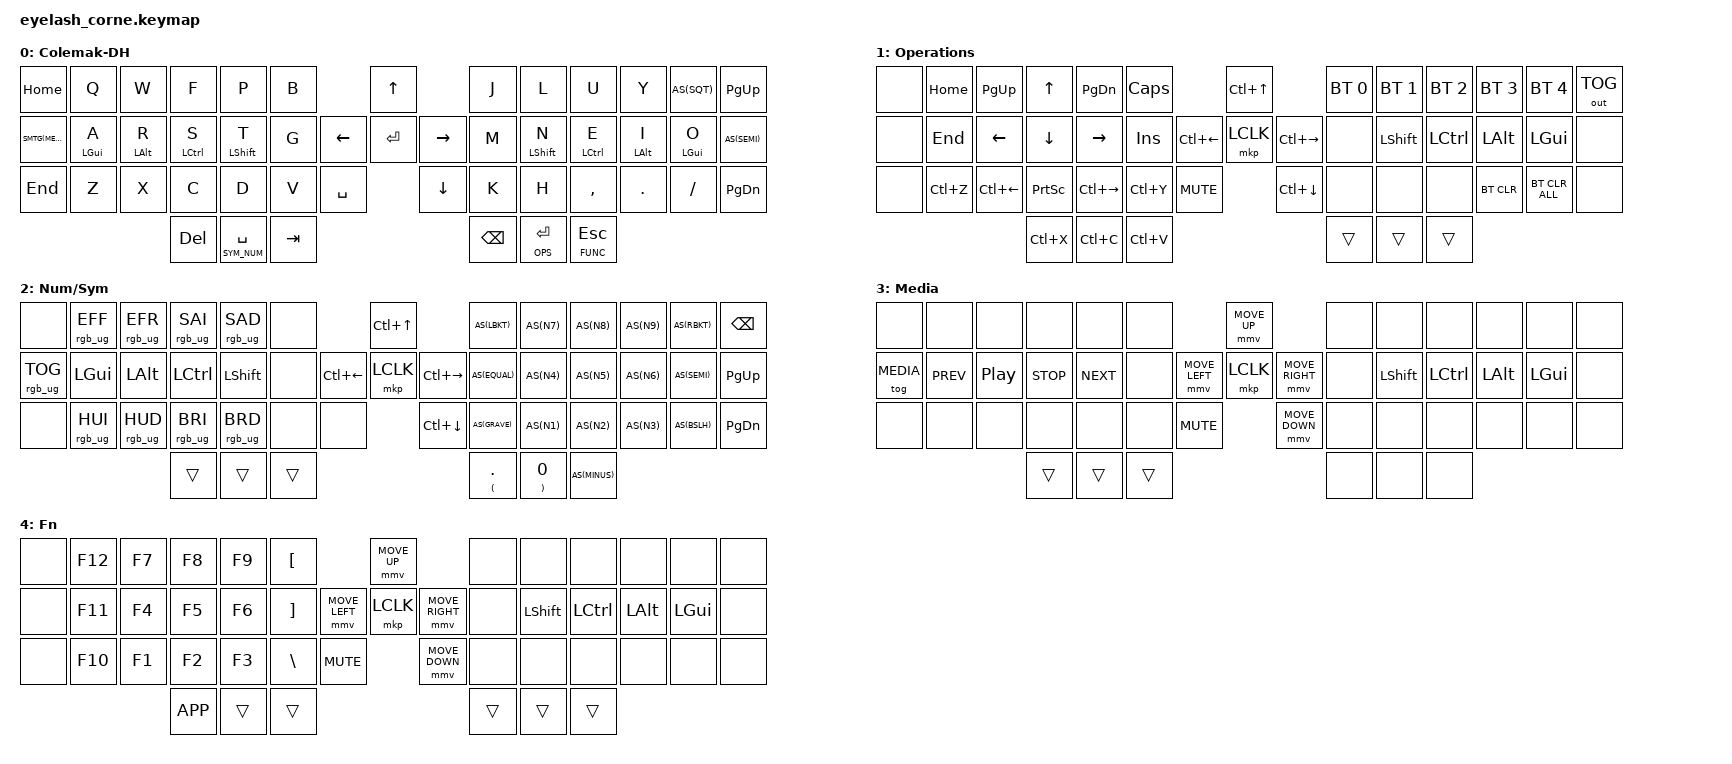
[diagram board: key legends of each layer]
#define ZMK_POINTING_DEFAULT_MOVE_VAL 1200  // 600
#define ZMK_POINTING_DEFAULT_SCRL_VAL 25   // 10

#define AS(keycode)     &as LS(keycode) keycode     // Autoshift Macro
#define SMTG(keycode)   &smtg keycode keycode

/*                42 KEY MATRIX with ENCODER and JOYSTICK / LAYOUT MAPPING

based on Aliexpress variation of Foostan corne
https://github.com/a741725193/zmk-new_corne/blob/main/README_EN.md

  ╭────────────────────────╮             ╭────╮      ╭─────────────────────────╮
  │  0   1   2   3   4   5 │         ╭───╯  6 ╰───╮  │   7   8   9  10  11  12 │
  │ 13  14  15  16  17  18 │ ╭────╮  │ 19  20  21 │  │  22  23  24  25  26  27 │
  │ 28  29  30  31  32  33 │ │ 34 │  ╰───╮ 35 ╭───╯  │  36  37  38  39  40  41 │
  ╰───────────╮ 42  43  44 │ ╰────╯      ╰────╯      │  45  46  47 ╭───────────╯
              ╰────────────╯                         ╰─────────────╯

  ╭──────────────────────────────╮              ╭─────╮      ╭──────────────────────────────╮
  │ LT5  LT4  LT3  LT2  LT1  LT0 │          ╭───╯ JS0 ╰───╮  │ RT0  RT1  RT2  RT3  RT4  RT5 │
  │ LM5  LM4  LM3  LM2  LM1  LM0 │ ╭─────╮  │ JS1 JS2 JS3 │  │ RM0  RM1  RM2  RM3  RM4  RM5 │
  │ LB5  LB4  LB3  LB2  LB1  LB0 │ │ LEC │  ╰───╮ JS4 ╭───╯  │ RB0  RB1  RB2  RB3  RB4  RB5 │
  ╰──────────────╮ LH2  LH1  LH0 │ ╰─────╯      ╰─────╯      │ RH0  RH1  RH2 ╭──────────────╯
                 ╰───────────────╯                           ╰───────────────╯

*/

#define KEYS_L LT0 LT1 LT2 LT3 LT4 LT5 LM0 LM1 LM2 LM3 LM4 LM5 LB0 LB1 LB2 LB3 LB4 LB5
#define KEYS_R RT0 RT1 RT2 RT3 RT4 RT5 RM0 RM1 RM2 RM3 RM4 RM5 RB0 RB1 RB2 RB3 RB4 RB5
#define HMOD_L LM1 LM2 LM3 LM4
#define HMOD_R RM1 RM2 RM3 RM4
#define THUMB_L LH2 LH1 LH0
#define THUMB_R RH0 RH1 RH2

#define COL_DH  0
#define OPS     1
#define SYM_NUM 2
#define MEDIA   3
#define FUNC    4

#include <input/processors.dtsi>
#include <zephyr/dt-bindings/input/input-event-codes.h>
#include <behaviors.dtsi>
#include <dt-bindings/zmk/bt.h>
#include <dt-bindings/zmk/keys.h>
#include <dt-bindings/zmk/outputs.h>
#include <dt-bindings/zmk/pointing.h>
#include <dt-bindings/zmk/rgb.h>
#include <zmk-helpers/helper.h>
#include <zmk-helpers/key-labels/eyelash42.h>

&mmv_input_listener { input-processors = <&zip_xy_scaler 2 1>; };

&msc_input_listener { input-processors = <&zip_scroll_scaler 2 1>; };

&msc {
    acceleration-exponent = <1>;      // 0
    time-to-max-speed-ms = <100>;       // 300
    delay-ms = <0>;                   // 0
};

&mmv {
    time-to-max-speed-ms = <500>;
    acceleration-exponent = <1>;
    trigger-period-ms = <16>;
};

&soft_off { hold-time-ms = <2000>; };

&lt {
    tapping-term-ms = <175>;
};
&sl {
    release-after-ms = <2000>;
};

/ {
    behaviors {
        as: auto_shift {
            compatible = "zmk,behavior-hold-tap";
            #binding-cells = <2>;
            tapping-term-ms = <175>;
            flavor = "tap-preferred";
            bindings = <&kp>, <&kp>;
        };
        lhm: left_homerow_mods {
            compatible = "zmk,behavior-hold-tap";
            #binding-cells = <2>;
            tapping-term-ms = <175>;
            // require-prior-idle-ms = <125>;
            flavor = "tap-preferred";
            bindings = <&kp>, <&kp>;
            hold-trigger-key-positions = <KEYS_R THUMB_R HMOD_L>;
        };
        lhms: left_homerow_mod_shift {
            compatible = "zmk,behavior-hold-tap";
            #binding-cells = <2>;
            tapping-term-ms = <150>;
            flavor = "balanced";
            bindings = <&kp>, <&kp>;
            hold-trigger-key-positions = <KEYS_R THUMB_R LM3>;
            hold-trigger-on-release;
        };
        rhm: right_homerow_mods {
            compatible = "zmk,behavior-hold-tap";
            #binding-cells = <2>;
            tapping-term-ms = <175>;
            // require-prior-idle-ms = <125>;
            quick-tap-ms = <0>;
            flavor = "tap-preferred";
            bindings = <&kp>, <&kp>;
            hold-trigger-key-positions = <KEYS_L THUMB_L HMOD_R>;
        };
        rhms: right_homerow_mods_shift {
            compatible = "zmk,behavior-hold-tap";
            #binding-cells = <2>;
            tapping-term-ms = <150>;
            quick-tap-ms = <0>;
            flavor = "balanced";
            bindings = <&kp>, <&kp>;
            hold-trigger-key-positions = <KEYS_L THUMB_L RM1>;
            hold-trigger-on-release;
        };
        smtg: sticky_media_toggle {
            compatible = "zmk,behavior-hold-tap";
            #binding-cells = <2>;
            flavor = "hold-preferred";
            tapping-term-ms = <200>;
            bindings = <&tog>, <&sl>;
        };
    };
    rgb_encoder: rgb_encoder {
        compatible = "zmk,behavior-sensor-rotate";
        #sensor-binding-cells = <0>;
        bindings = <&rgb_ug RGB_BRI>, <&rgb_ug RGB_BRD>;
    };

    scroll_encoder: scroll_encoder {
        compatible = "zmk,behavior-sensor-rotate";
        #sensor-binding-cells = <0>;
        bindings = <&msc SCRL_DOWN>, <&msc SCRL_UP>;

        tap-ms = <100>;
    };

    combos {
        compatible = "zmk,combos";

        softoff {
            bindings = <&soft_off>;
            key-positions = <1 15 29>;
        };
        combo_caps_word {
            timeout-ms = <50>;
            key-positions = <17 23>;
            bindings = <&caps_word>;
        };
    };

    keymap {
        compatible = "zmk,keymap";

        default_layer {
            display-name = "Colemak-DH";
            bindings = <
&kp HOME   &kp Q       &kp W       &kp F               &kp P           &kp B                               &kp UP                &kp J        &kp L        &kp U           &kp Y       AS(SQT)     &kp PG_UP
SMTG(MEDIA) &lhm LGUI A &lhm LALT R &lhm LCTRL S        &lhms LSHFT T   &kp G                     &kp LEFT  &kp ENTER  &kp RIGHT  &kp M        &rhms LSHFT N &rhm LCTRL E    &rhm LALT I &rhm LGUI O AS(SEMI)
&kp END    &kp Z       &kp X       &kp C               &kp D           &kp V        &kp SPACE              &kp DOWN              &kp K        &kp H        &kp COMMA       &kp DOT     &kp FSLH    &kp PG_DN
                        &kp DEL     &lt SYM_NUM SPACE   &kp TAB                                                                   &kp BSPC     &lt OPS RET  &lt FUNC ESC
            >;

             sensor-bindings = <&scroll_encoder>;
        };

        ops_layer {
            display-name = "Operations";
            bindings = <
&none   &kp HOME        &kp PG_UP   &kp UP      &kp PG_DN       &kp CAPS                                        &kp LC(UP)                     &bt BT_SEL 0 &bt BT_SEL 1    &bt BT_SEL 2    &bt BT_SEL 3    &bt BT_SEL 4    &out OUT_TOG
&none   &kp END         &kp LEFT    &kp DOWN    &kp RIGHT       &kp INS                         &kp LC(LEFT)    &mkp LCLK       &kp LC(RIGHT)  &none        &kp LSHFT       &kp LCTRL       &kp LALT        &kp LGUI        &none
&none   &kp LC(Z)       &kp LC(LEFT) &kp PSCRN  &kp LC(RIGHT)   &kp LC(Y)       &kp C_MUTE                      &kp LC(DOWN)                   &none        &none           &none           &bt BT_CLR      &bt BT_CLR_ALL  &none
                                    &kp LC(X)   &kp LC(C)       &kp LC(V)                                                                      &trans       &trans          &trans
            >;

            sensor-bindings = <&scroll_encoder>;
        };

        num_sym_layer {
            display-name = "Num/Sym";
            bindings = <
&none                   &rgb_ug RGB_EFF     &rgb_ug RGB_EFR     &rgb_ug RGB_SAI     &rgb_ug RGB_SAD     &none                           &kp LC(UP)                      AS(LBKT)         AS(N7)           AS(N8)           AS(N9)           AS(RBKT)  &kp BSPC
&rgb_ug RGB_TOG         &kp LGUI            &kp LALT            &kp LCTRL           &kp LSHFT           &none           &kp LC(LEFT)    &mkp LCLK       &kp LC(RIGHT)   AS(EQUAL)        AS(N4)           AS(N5)           AS(N6)           AS(SEMI)  &kp PG_UP
&none                   &rgb_ug RGB_HUI     &rgb_ug RGB_HUD     &rgb_ug RGB_BRI     &rgb_ug RGB_BRD     &none  &none                    &kp LC(DOWN)                    AS(GRAVE)        AS(N1)           AS(N2)           AS(N3)           AS(BSLH)   &kp PG_DN
                                            &trans              &trans              &trans                                                                               &as LPAR DOT     &as RPAR N0      AS(MINUS)
            >;

            sensor-bindings = <&scroll_encoder>;
        };

        media_layer {
            display-name = "Media";
            bindings = <
&none       &none       &none       &none       &none       &none                                   &mmv MOVE_UP                     &none      &none       &none       &none       &none       &none
&tog MEDIA  &kp C_PREV  &kp C_PP    &kp C_STOP  &kp C_NEXT  &none                   &mmv MOVE_LEFT  &mkp LCLK       &mmv MOVE_RIGHT  &none      &kp LSHFT   &kp LCTRL   &kp LALT    &kp LGUI    &none
&none       &none       &none       &none       &none       &none      &kp C_MUTE                   &mmv MOVE_DOWN                   &none      &none       &none       &none       &none       &none
                                    &trans      &trans      &trans                                                                   &none      &none       &none
            >;

            sensor-bindings = <&inc_dec_kp C_VOLUME_UP C_VOLUME_DOWN>;
        };

        fn_layer {
            display-name = "Fn";
            bindings = <
&none   &kp F12     &kp F7      &kp F8      &kp F9  &kp LBKT                                    &mmv MOVE_UP                     &none      &none       &none       &none       &none       &none
&none   &kp F11     &kp F4      &kp F5      &kp F6  &kp RBKT                    &mmv MOVE_LEFT  &mkp LCLK       &mmv MOVE_RIGHT  &none      &kp LSHFT   &kp LCTRL   &kp LALT    &kp LGUI    &none
&none   &kp F10     &kp F1      &kp F2      &kp F3  &kp BSLH  &kp C_MUTE                        &mmv MOVE_DOWN                   &none      &none       &none       &none       &none       &none
                    &kp K_APP   &trans      &trans                                                                               &trans     &trans      &trans
            >;

            sensor-bindings = <&scroll_encoder>;
        };

    };
};
